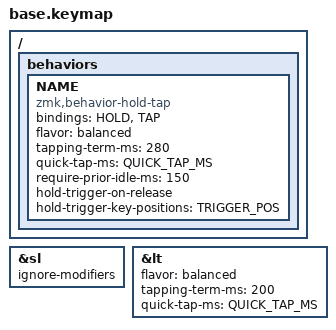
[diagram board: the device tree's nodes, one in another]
// clang-format off
#include <behaviors.dtsi>
#include <behaviors/num_word.dtsi>
#include <behaviors/unicode.dtsi>
#include <zmk-helpers/helper.h>
#include <dt-bindings/zmk/bt.h>
#include <dt-bindings/zmk/keys.h>

#define QUICK_TAP_MS 175

#define BASE 0
#define NAV 1
#define NUM 2
#define FN 3
#define SYS 4
#define MOUSE 5
#define GAMING 6

#define XXX &none
#define ___ &trans

&sl {
  ignore-modifiers;
};

&lt {
  flavor = "balanced";
  tapping-term-ms = <200>;
  quick-tap-ms = <QUICK_TAP_MS>;
};

#define MAKE_HRM(NAME, HOLD, TAP, TRIGGER_POS)                          \
  ZMK_HOLD_TAP(NAME, bindings = <HOLD>, <TAP>; flavor = "balanced";     \
                tapping-term-ms = <280>; quick-tap-ms = <QUICK_TAP_MS>; \
                require-prior-idle-ms = <150>; hold-trigger-on-release; \
                hold-trigger-key-positions = <TRIGGER_POS>;)

MAKE_HRM(hml, &kp, &kp, KEYS_R THUMBS) // Left-hand HRMs.
MAKE_HRM(hmr, &kp, &kp, KEYS_L THUMBS) // Right-hand HRMs.

#ifndef ZMK_BASE_LAYER
    #define ZMK_BASE_LAYER(name, LN, RN, LT, RT, LM, RM, LB, RB, LF, RF, LHT, RHT, LHB, RHB)    \
        ZMK_LAYER(name, LN RN LT RT LM RM LB RB LF RF LHT RHT LHB RHB)
#endif

ZMK_BASE_LAYER(Base,
//╭─────────────┬─────────────┬─────────────┬─────────────┬─────────────┬─────────────╮ ╭─────────────┬─────────────┬─────────────┬─────────────┬─────────────┬─────────────╮
    &kp ESC         &kp N1        &kp N2        &kp N3        &kp N4       &kp N5     ,    &kp N6         &kp N7        &kp N8        &kp N9        &kp N0        &kp GRAVE ,
//├─────────────┼─────────────┼─────────────┼─────────────┼─────────────┼─────────────┤ ├─────────────┼─────────────┼─────────────┼─────────────┼─────────────┼─────────────┤
    &kp TAB         &kp Q         &kp W         &kp E         &kp R        &kp T      ,    &kp Y          &kp U         &kp I         &kp O         &kp P         &kp BSLH  ,
//├─────────────┼─────────────┼─────────────┼─────────────┼─────────────┼─────────────┤ ├─────────────┼─────────────┼─────────────┼─────────────┼─────────────┼─────────────┤
    &kp LSHFT     &hml LGUI A   &hml LALT S   &hml LSHFT D  &hml LCTRL F   &kp G      ,    &kp H        &hmr LCTRL J &hmr RSHFT K   &hmr LALT L  &hmr LGUI SEMI   &kp SQT   ,
//├─────────────┼─────────────┼─────────────┼─────────────┼─────────────┼─────────────┤ ├─────────────┼─────────────┼─────────────┼─────────────┼─────────────┼─────────────┤
    &kp LCTRL       &kp Z         &kp X         &kp C         &kp V        &kp B      ,    &kp N          &kp M       &kp COMMA      &kp DOT        &kp FSLH      &kp RSHFT ,
//╰─────────────┴─────────────┼─────────────┼─────────────┼─────────────┴─────────────╯ ╰─────────────┴─────────────┼─────────────┼─────────────┼─────────────┴─────────────╯
                                  &kp LBKT      &kp RBKT                              ,                                &kp MINUS     &kp EQUAL  ,
//                            ╰─────────────┴─────────────╯                                                         ╰─────────────┴─────────────╯
//                                          ╭─────────────┬─────────────┬─────────────╮ ╭─────────────┬─────────────┬─────────────╮
                                                  &kp N0     &kp SPACE     &kp DEL    ,    &kp BSPC      &kp RETURN      &kp N0   ,
//                                          ╰─────────────┼─────────────┼─────────────┤ ├─────────────┼─────────────┼─────────────╯
                                                             &bootloader   &kp LGUI   ,    &kp RGUI     &bootloader
//                                                        ╰─────────────┴─────────────╯ ╰─────────────┴─────────────╯
)

// / {
//   keymap {
//     compatible = "zmk,keymap";
//     default_layer {
//       bindings = <&kp ESC &kp N1 &kp N2 &kp N3 &kp N4 &kp N5      &kp N6 &kp N7 &kp N8 &kp N9 &kp N0 &kp GRAVE
//       &kp TAB &kp Q &kp W &kp E &kp R &kp T                       &kp Y &kp U &kp I &kp O &kp P &kp BSLH
//       &kp LSHFT &kp A &kp S &kp D &kp F &kp G                     &kp H &kp J &kp K &kp L &kp SEMI &kp SQT
//       &kp LCTRL &kp Z &kp X &kp C &kp V &kp B                     &kp N &kp M &kp COMMA &kp DOT &kp FSLH &kp RSHFT
//                       &kp LBKT &kp RBKT                                       &kp MINUS &kp EQUAL
//                       &kp N0 &kp SPACE &kp DEL                    &kp BSPC &kp RETURN &kp N2
//                              &bootloader &kp LGUI                 &kp RGUI &bootloader>;
//     };
//   };
// };
// clang-format on

/* vim: set ft=c tw=146: */
